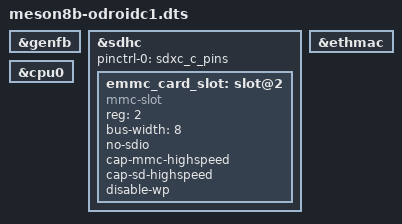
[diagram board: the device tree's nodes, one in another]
/* $NetBSD: meson8b-odroidc1.dts,v 1.3.6.4 2020/04/13 08:03:33 martin Exp $ */

/*-
 * Copyright (c) 2019 Jared McNeill <jmcneill@invisible.ca>
 * All rights reserved.
 *
 * Redistribution and use in source and binary forms, with or without
 * modification, are permitted provided that the following conditions
 * are met:
 * 1. Redistributions of source code must retain the above copyright
 *    notice, this list of conditions and the following disclaimer.
 * 2. Redistributions in binary form must reproduce the above copyright
 *    notice, this list of conditions and the following disclaimer in the
 *    documentation and/or other materials provided with the distribution.
 *
 * THIS SOFTWARE IS PROVIDED BY THE AUTHOR ``AS IS'' AND ANY EXPRESS OR
 * IMPLIED WARRANTIES, INCLUDING, BUT NOT LIMITED TO, THE IMPLIED WARRANTIES
 * OF MERCHANTABILITY AND FITNESS FOR A PARTICULAR PURPOSE ARE DISCLAIMED.
 * IN NO EVENT SHALL THE AUTHOR BE LIABLE FOR ANY DIRECT, INDIRECT,
 * INCIDENTAL, SPECIAL, EXEMPLARY, OR CONSEQUENTIAL DAMAGES (INCLUDING,
 * BUT NOT LIMITED TO, PROCUREMENT OF SUBSTITUTE GOODS OR SERVICES;
 * LOSS OF USE, DATA, OR PROFITS; OR BUSINESS INTERRUPTION) HOWEVER CAUSED
 * AND ON ANY THEORY OF LIABILITY, WHETHER IN CONTRACT, STRICT LIABILITY,
 * OR TORT (INCLUDING NEGLIGENCE OR OTHERWISE) ARISING IN ANY WAY
 * OUT OF THE USE OF THIS SOFTWARE, EVEN IF ADVISED OF THE POSSIBILITY OF
 * SUCH DAMAGE.
 */

#include "../../../external/gpl2/dts/dist/arch/arm/boot/dts/meson8b-odroidc1.dts"
#include "meson8b.dtsi"

&genfb {
	status = "okay";
};

&sdhc {
	status = "okay";

	pinctrl-0 = <&sdxc_c_pins>;
	pinctrl-names = "default";

	/* eMMC card */
	emmc_card_slot: slot@2 {
		compatible = "mmc-slot";
		reg = <2>;
		status = "okay";

		bus-width = <8>;
		no-sdio;
		cap-mmc-highspeed;
		cap-sd-highspeed;
		disable-wp;
	};
};

&ethmac {
	/delete-property/ snps,reset-gpio;
	/delete-property/ snps,reset-active-low;
	/delete-property/ snps,reset-delays-us;
};

&cpu0 {
	/delete-property/ cpu-supply;
};
